AUTOSAR XML (schema 314)
package /ComponentType
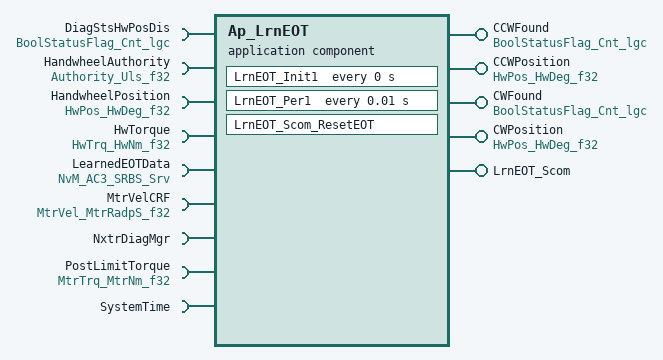
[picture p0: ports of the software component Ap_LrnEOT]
  application software component type Ap_LrnEOT
    5 x provide port:
      CCWFound: unqueued-sender-com-spec{data-element=Cnt_lgc, can-invalidate=false, init-value=D_FALSE_CNT_LGC}, provided-interface=BoolStatusFlag_Cnt_lgc
      CCWPosition: unqueued-sender-com-spec{data-element=HwDeg_f32, can-invalidate=false, init-value=D_ZERO_ULS_F32}, provided-interface=HwPos_HwDeg_f32
      CWFound: unqueued-sender-com-spec{data-element=Cnt_lgc, can-invalidate=false, init-value=D_FALSE_CNT_LGC}, provided-interface=BoolStatusFlag_Cnt_lgc
      CWPosition: unqueued-sender-com-spec{data-element=HwDeg_f32, can-invalidate=false, init-value=D_ZERO_ULS_F32}, provided-interface=HwPos_HwDeg_f32
      LrnEOT_Scom: provided-com-specs=[{operation=ResetEOT, queue-length=1}, {operation=ResetRckCntrPrf, queue-length=1}], provided-interface=LrnEOT_Scom
    9 x require port:
      DiagStsHwPosDis: unqueued-receiver-com-spec{data-element=Cnt_lgc, init-value=D_FALSE_CNT_LGC}, required-interface=BoolStatusFlag_Cnt_lgc
      HandwheelAuthority: unqueued-receiver-com-spec{data-element=Uls_f32, init-value=D_ZERO_ULS_F32}, required-interface=Authority_Uls_f32
      HandwheelPosition: unqueued-receiver-com-spec{data-element=HwDeg_f32, init-value=D_ZERO_ULS_F32}, required-interface=HwPos_HwDeg_f32
      HwTorque: unqueued-receiver-com-spec{data-element=HwNm_f32, init-value=D_ZERO_ULS_F32}, required-interface=HwTrq_HwNm_f32
      LearnedEOTData: required-com-specs=[EraseBlock, GetErrorStatus, InvalidateNvBlock, ReadBlock, SetRamBlockStatus, WriteBlock], required-interface=NvM_AC3_SRBS_Srv
      MtrVelCRF: unqueued-receiver-com-spec{data-element=MtrRadpS_f32, init-value=D_ZERO_ULS_F32}, required-interface=MtrVel_MtrRadpS_f32
      NxtrDiagMgr: required-com-specs=[GetNTCActive, GetNTCFailed, GetNTCStatus, SetNTCStatus], required-interface=NxtrDiagMgr
      PostLimitTorque: unqueued-receiver-com-spec{data-element=MtrNm_f32, init-value=D_ZERO_ULS_F32}, required-interface=MtrTrq_MtrNm_f32
      SystemTime: required-interface=SystemTime
        required-com-specs:
          DtrmnElapsedTime_mS_u16
          DtrmnElapsedTime_mS_u32
          DtrmnElapsedTime_uS_u16
          DtrmnElapsedTime_uS_u32
          GetSystemTime_mS_u32
          GetSystemTime_uS_u32
  internal behavior Ap_LrnEOT_InternalBehavior: component=Ap_LrnEOT
    timing event LrnEOT_Init1_InitEvent: start-on-event=LrnEOT_Init1, period=0
    timing event TMT_LrnEOT_Per1: start-on-event=LrnEOT_Per1, period=0.01
    operation invoked event OIT_LrnEOT_Scom_ResetEOT_LrnEOT_Scom_ResetEOT: start-on-event=LrnEOT_Scom_ResetEOT, operation=LrnEOT_Scom.ResetEOT
    per instance memory LearnedEOT: type=EOTLearned_DataType, type-definition=/DataType/EOTLearned_DataType
    port-api-options:
      enable-take-address=false, indirect-api=false, port=CCWFound
      enable-take-address=false, indirect-api=false, port=CCWPosition
      enable-take-address=false, indirect-api=false, port=CWFound
      enable-take-address=false, indirect-api=false, port=CWPosition
      enable-take-address=false, indirect-api=false, port=DiagStsHwPosDis
      enable-take-address=false, indirect-api=false, port=HandwheelAuthority
      enable-take-address=false, indirect-api=false, port=HandwheelPosition
      enable-take-address=false, indirect-api=false, port=HwTorque
      enable-take-address=false, indirect-api=false, port=LearnedEOTData
      enable-take-address=false, indirect-api=false, port=LrnEOT_Scom
      enable-take-address=false, indirect-api=false, port=MtrVelCRF
      enable-take-address=false, indirect-api=false, port=NxtrDiagMgr
      enable-take-address=false, indirect-api=false, port=PostLimitTorque
      enable-take-address=false, indirect-api=false, port=SystemTime
    runnable LrnEOT_Init1
      4 x data write access:
        WRITE_CCWFound_Cnt_lgc: data-element=CCWFound.Cnt_lgc
        WRITE_CCWPosition_HwDeg_f32: data-element=CCWPosition.HwDeg_f32
        WRITE_CWFound_Cnt_lgc: data-element=CWFound.Cnt_lgc
        WRITE_CWPosition_HwDeg_f32: data-element=CWPosition.HwDeg_f32
      4 x sync call, all with timeout=0:
        SC_LearnedEOTData_SetRamBlockStatus: operation=LearnedEOTData.SetRamBlockStatus
        SC_LearnedEOTData_WriteBlock: operation=LearnedEOTData.WriteBlock
        SC_NxtrDiagMgr_GetNTCFailed: operation=NxtrDiagMgr.GetNTCFailed
        SC_SystemTime_GetSystemTime_mS_u32: operation=SystemTime.GetSystemTime_mS_u32
    runnable LrnEOT_Per1
      6 x data read access:
        READ_DiagStsHwPosDis_Cnt_lgc: data-element=DiagStsHwPosDis.Cnt_lgc
        READ_HandwheelAuthority_Uls_f32: data-element=HandwheelAuthority.Uls_f32
        READ_HandwheelPosition_HwDeg_f32: data-element=HandwheelPosition.HwDeg_f32
        READ_HwTorque_HwNm_f32: data-element=HwTorque.HwNm_f32
        READ_MtrVelCRF_MtrRadpS_f32: data-element=MtrVelCRF.MtrRadpS_f32
        READ_PostLimitTorque_MtrNm_f32: data-element=PostLimitTorque.MtrNm_f32
      4 x data write access:
        WRITE_CCWFound_Cnt_lgc: data-element=CCWFound.Cnt_lgc
        WRITE_CCWPosition_HwDeg_f32: data-element=CCWPosition.HwDeg_f32
        WRITE_CWFound_Cnt_lgc: data-element=CWFound.Cnt_lgc
        WRITE_CWPosition_HwDeg_f32: data-element=CWPosition.HwDeg_f32
      4 x sync call, all with timeout=0:
        SC_LearnedEOTData_SetRamBlockStatus: operation=LearnedEOTData.SetRamBlockStatus
        SC_LearnedEOTData_WriteBlock: operation=LearnedEOTData.WriteBlock
        SC_SystemTime_DtrmnElapsedTime_mS_u16: operation=SystemTime.DtrmnElapsedTime_mS_u16
        SC_SystemTime_GetSystemTime_mS_u32: operation=SystemTime.GetSystemTime_mS_u32
    runnable LrnEOT_Scom_ResetEOT
    service-needss:
      swc nv block needs EOTLearnedBlk: n-data-sets=0, readonly=false, reliability=LOW, resistant-to-changed-sw=false, restore-at-start=false, write-only-once=false, writing-frequency=0, writing-priority=LOW, mirror-block=LearnedEOT
  swc implementation Ap_LrnEOT_Implementation: behavior=Ap_LrnEOT_InternalBehavior
    code-descriptors:
      code Code: type=SRC
